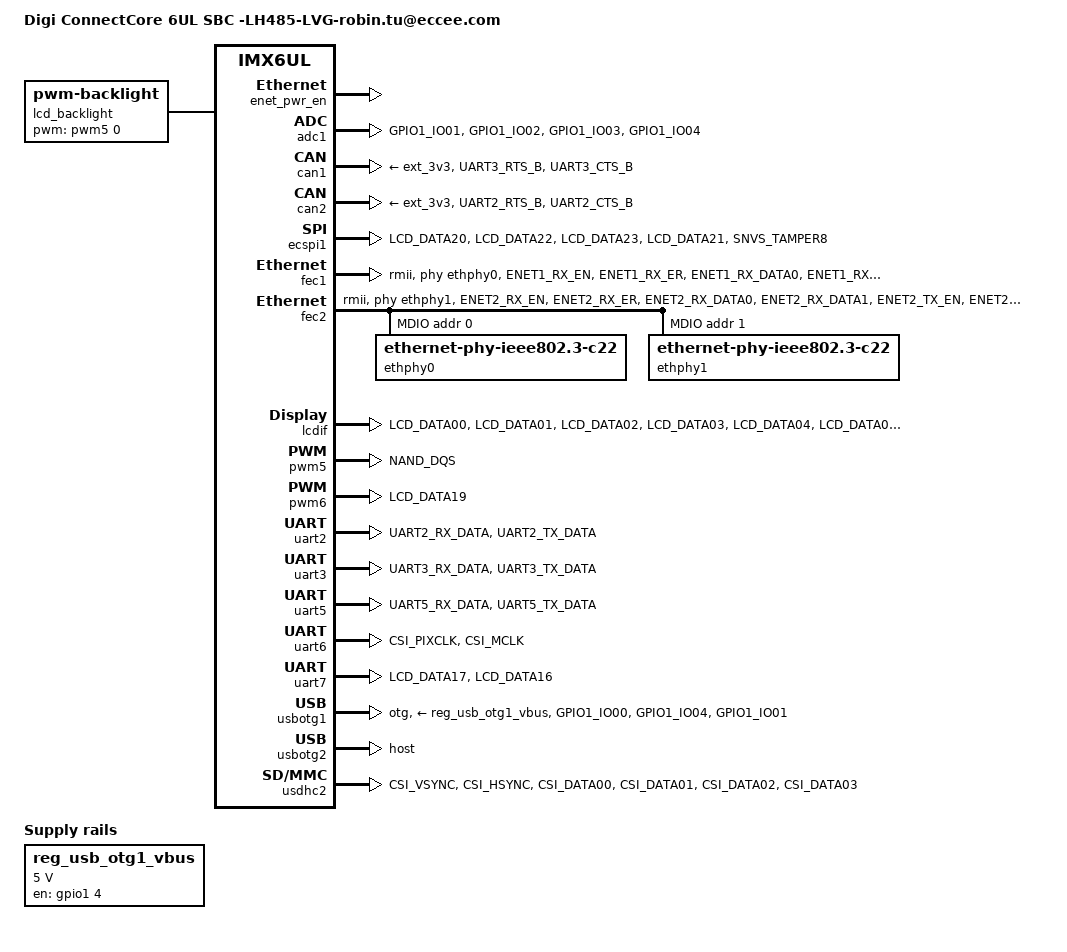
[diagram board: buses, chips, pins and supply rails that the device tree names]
/*
 * Device tree generated automatically by Digi ConnectCore Smart IOmux.
 *
 * This file is provided "AS IS" without any warranties and support, it is
 * just a guideline that requires additional customization.
 *
 * Please verify the calculated pin assignments with the hardware reference
 * manual for your platform, review the commented lines, and add the
 * specific values for your hardware.
 */

/dts-v1/;

#include <dt-bindings/input/input.h>
#include <dt-bindings/interrupt-controller/irq.h>
/* i.MX6 UltraLite CPU */
#include "imx6ul.dtsi"
/* ConnectCore 6UL (wireless/bluetooth variant) */
#include "imx6ul-ccimx6ul-wb.dtsi"

/ {
	// Add here your platform model.
	model = "Digi ConnectCore 6UL SBC -LH485-LVG-robin.tu@eccee.com ";
	// Add here your compatible platform.
	compatible = "digi,ccimx6ulsbc", "digi,ccimx6ul", "fsl,imx6ul";


	pxp_v4l2: pxp-v4l2 {
		compatible = "fsl,imx6ul-pxp-v4l2", "fsl,imx6sx-pxp-v4l2", "fsl,imx6sl-pxp-v4l2";
		status = "okay";
	};

	reg_usb_otg1_vbus: reg_usb_otg1@0 {
		compatible = "regulator-fixed";
		regulator-name = "usb_otg1_vbus";
		regulator-min-microvolt = <5000000>;
		regulator-max-microvolt = <5000000>;
		gpio = <&gpio1 4 GPIO_ACTIVE_HIGH>;
		enable-active-high;
	};

	sound_max98089: sound-max98089 {
		compatible = "fsl,imx-audio-max98088";
		model = "imx-max98088";
		cpu-dai = <&sai2>;
		audio-codec = <&max98089>;
		asrc-controller = <&asrc>;
		gpr = <&gpr>;
		audio-routing =
			"Headphone Jack", "HPL",
			"Headphone Jack", "HPR",
			"Ext Spk", "SPKL",
			"Ext Spk", "SPKR",
			"LineOut", "RECL",
			"LineOut", "RECR",
			"Mic1", "MIC1",
			"Mic2", "MIC2",
			"LineInA", "INA1",
			"LineInA", "INA2",
			"LineInB", "INB1",
			"LineInB", "INB2";
		status = "disabled";
	};

	enet_pwr_en {
                          enet-pwren-gpios = <&gpio1 5 GPIO_ACTIVE_HIGH>;
                          status = "okay";
	};

	lcd_backlight: backlight {
		compatible = "pwm-backlight";
		pwms = <&pwm5 0 50000>;
		brightness-levels = <0 4 8 16 32 64 128 255>;
		default-brightness-level = <6>;
		status = "okay";
	};
};

//&csi {
//	status = "disabled";
//
//	port {
//		csi_ep0: endpoint@0 {
//			remote-endpoint = <&ov5640_ep>;
//		};
//
//	};
//};

&adc1 {
	pinctrl-names = "default";
	pinctrl-0 = <&pinctrl_adc1>;
	adc-ch-list = <1 2 3 4>;
	status = "okay";
};

&can1 {
	pinctrl-names = "default";
	pinctrl-0 = <&pinctrl_flexcan1>;

	/*
	 * Optional field.
	 *
	 * Set the proper voltage regulator to power the
	 * transceiver if needed.
	 */
	xceiver-supply = <&ext_3v3>;

	status = "okay";
};

&can2 {
	pinctrl-names = "default";
	pinctrl-0 = <&pinctrl_flexcan2>;

	/*
	 * Optional field.
	 *
	 * Set the proper voltage regulator to power the
	 * transceiver if needed.
	 */
	xceiver-supply = <&ext_3v3>;

	status = "okay";
};

&ecspi1 {
	num-cs = <1>;
	cs-gpios = <&gpio3 26 GPIO_ACTIVE_LOW>;
	pinctrl-names = "default";
	status = "okay";

	/*
	 * Configure the GPIO that you selected as 'slave select'.
	 */
	//cs-gpios = <&gpio3 26 GPIO_ACTIVE_LOW>;

	/*
	 * ECSPI1 (as master)
	 */
	//pinctrl-0 = <&pinctrl_ecspi1>;
	pinctrl-0 = <&pinctrl_ecspi1_master>;

	/*
	 * Reference block.
	 *
	 * Add your slave devices here. Next is an example of spidev.
	 * Expect a harmless kernel warning if you enable spidev as slave.
	 */
	//spidev@0 {
	//	reg = <0>;
	//	compatible = "spidev";
	//	spi-max-frequency = <1000000>;
	//};

};

&fec1 {
	pinctrl-names = "default";
	pinctrl-0 = <&pinctrl_enet1>, <&pinctrl_enet1_gpio>;
	phy-mode = "rmii";
	phy-handle = <&ethphy0>;
	phy-reset-gpios = <&mca_gpio 7 GPIO_ACTIVE_LOW>;
	phy-reset-duration = <26>;
	digi,phy-reset-in-suspend;
	status = "okay";
};

&fec2 {
	pinctrl-names = "default";
	pinctrl-0 = <&pinctrl_enet2>,
		    <&pinctrl_enet2_mdio>,
		    <&pinctrl_enet2_gpio>;
	phy-mode = "rmii";
	phy-handle = <&ethphy1>;
	phy-reset-gpios = <&gpio5 6 GPIO_ACTIVE_LOW>;
	phy-reset-duration = <26>;
	digi,phy-reset-in-suspend;
	status = "okay";

	/*
	 * The MDIO bus is shared between ENET1 and ENET2. If you only want
	 * to enable ENET1, this node must be moved to fec1 node, and the
	 * pinctrl-0 of fec1 must contain the IOMUX for the MDIO bus on ENET1
	 * (pintrl_enet1_mdio).
	 */
	mdio {
		#address-cells = <1>;
		#size-cells = <0>;

		ethphy0: ethernet-phy@0 {
			compatible = "ethernet-phy-ieee802.3-c22";
			smsc,disable-energy-detect;
			reg = <0>;
		};

		ethphy1: ethernet-phy@1 {
			compatible = "ethernet-phy-ieee802.3-c22";
			smsc,disable-energy-detect;
			reg = <1>;
		};
	};
};


&i2c1 {

	max98089: codec@10 {
		compatible = "maxim,max98089";
		reg = <0x10>;
		clocks = <&clks IMX6UL_CLK_SAI2>;
		clock-names = "mclk";
		interrupt-parent = <&gpio5>;
		interrupts = <7 IRQ_TYPE_EDGE_FALLING>;
		status = "disabled";
	};

//	ov5640: ov5640@3c {
//		compatible = "ov5640";
//		reg = <0x3c>;
//		pinctrl-names = "default";
//		pinctrl-0 = <&pinctrl_csi>;
//		clocks = <&clks IMX6UL_CLK_CSI>;
//		clock-names = "csi_mclk";
//		pwn-gpios = <&mca_ioexp_gpio 31 GPIO_ACTIVE_LOW>;
//		rst-gpios = <&mca_ioexp_gpio 22 GPIO_ACTIVE_HIGH>;
//		csi_id = <0>;
//		mclk = <24000000>;
//		mclk_source = <0>;
//		status = "disabled";
//		digi,defer-probe;
//		port {
//			ov5640_ep: endpoint {
//				remote-endpoint = <&csi_ep0>;
//			};
//		};
//	};
};

&lcdif {
	pinctrl-names = "default";
	pinctrl-0 = <&pinctrl_lcdif>;
	/* Select one of the defined displays */
	display = <&hw480272>;
	status = "okay";

	/*
	 * Reference block.
	 *
	 * Define your display.
	 */
	hw480272: display@2 {
		bits-per-pixel = <16>;
		bus-width = <16>;

		display-timings {
			native-mode = <&timing3>;
			timing3: timing3 {
				clock-frequency = <9000000>;
				hactive = <480>;
				vactive = <272>;
				hfront-porch = <8>;
				hback-porch = <43>;
				hsync-len = <4>;
				vback-porch = <8>;
				vfront-porch = <8>;
				vsync-len = <6>;
				hsync-active = <0>;
				vsync-active = <0>;
				de-active = <1>;
				pixelclk-active = <0>;
			};
		};
	};
};

/* LCD backlight */
&pwm5 {
	pinctrl-names = "default";
	pinctrl-0 = <&pinctrl_pwm5>;
	status = "okay";
};

&pwm6 {
	pinctrl-names = "default";
	pinctrl-0 = <&pinctrl_pwm6>;
	status = "okay";
};

/* SAI2 */
&sai2 {
	pinctrl-names = "default", "sleep";
	pinctrl-0 = <&pinctrl_sai2>;
	pinctrl-1 = <&pinctrl_sai2_sleep>;
	assigned-clocks = <&clks IMX6UL_CLK_SAI2_SEL>,
			  <&clks IMX6UL_CLK_PLL4_AUDIO_DIV>,
			  <&clks IMX6UL_CLK_SAI2>;
	assigned-clock-rates = <0>, <786432000>, <12288000>;
	assigned-clock-parents = <&clks IMX6UL_CLK_PLL4_AUDIO_DIV>;
	status = "disabled";
};

&uart2 {
	pinctrl-names = "default";
	pinctrl-0 = <&pinctrl_uart2>;

	status = "okay";
};

&uart3 {
	pinctrl-names = "default";
	pinctrl-0 = <&pinctrl_uart3>;

	status = "okay";
};

&uart5 {
	pinctrl-names = "default";
	pinctrl-0 = <&pinctrl_console>;
	status = "okay";
};

&uart6 {
	pinctrl-names = "default";
	pinctrl-0 = <&pinctrl_uart6>;

	status = "okay";
};

&uart7 {
	pinctrl-names = "default";
	pinctrl-0 = <&pinctrl_uart7>;

	status = "okay";
};

&usbotg1 {
	dr_mode = "otg";

	/* Set the proper voltage regulator. */
	vbus-supply = <&reg_usb_otg1_vbus>;

	/*
	 * Configure the power line if needed.
	 */
	digi,power-line-active-high;

	/*
	 * Configure the overcurrent line if needed.
	 */
	//disable-over-current;

	pinctrl-0 = <&pinctrl_usbotg1>;

	status = "okay";
};

&usbotg2 {
	dr_mode = "host";

	/* Set the proper voltage regulator. */
	//vbus-supply = <&reg_usb_otg1_vbus>;

	/*
	 * Configure the power line if needed.
	 */
	digi,power-line-active-high;

	/*
	 * Configure the overcurrent line if needed.
	 */
	disable-over-current;

	status = "okay";
};

&usdhc2 {
	pinctrl-names = "default";
	pinctrl-0 = <&pinctrl_usdhc2>;
	//pinctrl-assert-gpios = <&gpio5 1 GPIO_ACTIVE_LOW>;
	broken-cd;      /* no carrier detect line (use polling) */
	no-1-8-v;
	status = "okay";
};

&iomuxc {
	pinctrl-names = "default";
	pinctrl-0 = <&pinctrl_hog>;

	imx6ul-ccimx6ul {
		pinctrl_adc1: adc1grp {
			fsl,pins = <
				MX6UL_PAD_GPIO1_IO01__GPIO1_IO01		0xb0
				MX6UL_PAD_GPIO1_IO02__GPIO1_IO02		0xb0
				MX6UL_PAD_GPIO1_IO03__GPIO1_IO03		0xb0
				MX6UL_PAD_GPIO1_IO04__GPIO1_IO04		0xb0
			>;
		};

		pinctrl_console: uart5grp {
			fsl,pins = <
				MX6UL_PAD_UART5_RX_DATA__UART5_DCE_RX		0x1b0b1
				MX6UL_PAD_UART5_TX_DATA__UART5_DCE_TX		0x1b0b1
			>;
		};

		pinctrl_ecspi1_master: ecspi1grp1 {
			fsl,pins = <
				MX6UL_PAD_LCD_DATA20__ECSPI1_SCLK	0x10b0
				MX6UL_PAD_LCD_DATA22__ECSPI1_MOSI	0x10b0
				MX6UL_PAD_LCD_DATA23__ECSPI1_MISO	0x10b0
				MX6UL_PAD_LCD_DATA21__GPIO3_IO26	0x10b0 /* Chip Select */
				/* SPI1_IRQ_N */
				MX6UL_PAD_SNVS_TAMPER8__GPIO5_IO08	0x1b0b0
			>;
		};
		
		pinctrl_ecspi1_slave: ecspi1grp2 {
			fsl,pins = <
				MX6UL_PAD_LCD_DATA20__ECSPI1_SCLK	0x10b0
				MX6UL_PAD_LCD_DATA22__ECSPI1_MOSI	0x10b0
				MX6UL_PAD_LCD_DATA23__ECSPI1_MISO	0x10b0
				MX6UL_PAD_LCD_DATA21__ECSPI1_SS0	0x10b0 /* Chip Select */
				/* SPI1_IRQ_N */
				MX6UL_PAD_SNVS_TAMPER8__GPIO5_IO08	0x1b0b0
			>;
		};

		pinctrl_enet1: enet1grp {
			fsl,pins = <
				MX6UL_PAD_ENET1_RX_EN__ENET1_RX_EN	0x1b0b0
				MX6UL_PAD_ENET1_RX_ER__ENET1_RX_ER	0x1b0b0
				MX6UL_PAD_ENET1_RX_DATA0__ENET1_RDATA00	0x1b0b0
				MX6UL_PAD_ENET1_RX_DATA1__ENET1_RDATA01	0x1b0b0
				MX6UL_PAD_ENET1_TX_EN__ENET1_TX_EN	0x1b0b0
				MX6UL_PAD_ENET1_TX_DATA0__ENET1_TDATA00	0x1b0b0
				MX6UL_PAD_ENET1_TX_DATA1__ENET1_TDATA01	0x1b0b0
				MX6UL_PAD_ENET1_TX_CLK__ENET1_REF_CLK1	0x4001b031
			>;
		};

		pinctrl_enet2: enet2grp {
			fsl,pins = <
				MX6UL_PAD_ENET2_RX_EN__ENET2_RX_EN	0x1b0b0
				MX6UL_PAD_ENET2_RX_ER__ENET2_RX_ER	0x1b0b0
				MX6UL_PAD_ENET2_RX_DATA0__ENET2_RDATA00	0x1b0b0
				MX6UL_PAD_ENET2_RX_DATA1__ENET2_RDATA01	0x1b0b0
				MX6UL_PAD_ENET2_TX_EN__ENET2_TX_EN	0x1b0b0
				MX6UL_PAD_ENET2_TX_DATA0__ENET2_TDATA00	0x1b0b0
				MX6UL_PAD_ENET2_TX_DATA1__ENET2_TDATA01	0x1b0b0
				MX6UL_PAD_ENET2_TX_CLK__ENET2_REF_CLK2	0x4001b031
			>;
		};

		pinctrl_enet1_mdio: mdioenet1grp {
			fsl,pins = <
				MX6UL_PAD_GPIO1_IO07__ENET1_MDC		0x1b0b0
				MX6UL_PAD_GPIO1_IO06__ENET1_MDIO	0x1b0b0
			>;
		};

		pinctrl_enet2_mdio: mdioenet2grp {
			fsl,pins = <
				MX6UL_PAD_GPIO1_IO07__ENET2_MDC		0x1b0b0
				MX6UL_PAD_GPIO1_IO06__ENET2_MDIO	0x1b0b0
			>;
		};

		pinctrl_enet1_gpio: enet1gpiogrp {
			fsl,pins = <
				/* ENET1_INT */
				MX6UL_PAD_GPIO1_IO08__GPIO1_IO08	0x1b0b0
			>;
		};

		pinctrl_enet2_gpio: enet2gpiogrp {
			fsl,pins = <
				/* PHY reset */
				MX6UL_PAD_SNVS_TAMPER6__GPIO5_IO06	0x0b0b0
				/* ENET2_INT */
				MX6UL_PAD_GPIO1_IO09__GPIO1_IO09	0x1b0b0
			>;
		};

		pinctrl_flexcan1: flexcan1grp {
			fsl,pins = <
				MX6UL_PAD_UART3_RTS_B__FLEXCAN1_RX		0x1b020
				MX6UL_PAD_UART3_CTS_B__FLEXCAN1_TX		0x1b020
			>;
		};

		pinctrl_flexcan2: flexcan2grp {
			fsl,pins = <
				MX6UL_PAD_UART2_RTS_B__FLEXCAN2_RX		0x1b020
				MX6UL_PAD_UART2_CTS_B__FLEXCAN2_TX		0x1b020
			>;
		};

        pinctrl_hog: hoggrp {
            fsl,pins = <
		/* GPIO1_IO05[ENET_PWR_EN] */
                MX6UL_PAD_GPIO1_IO05__GPIO1_IO05                0x1b0b0
                /* GPIO5_IO05[EXP_I2C_IRQ_N] */
                MX6UL_PAD_SNVS_TAMPER5__GPIO5_IO05              0x1b0b0
            >;
                };


		pinctrl_lcdif: lcdifgrp {
			fsl,pins = <
				MX6UL_PAD_LCD_DATA00__LCDIF_DATA00		0x79
				MX6UL_PAD_LCD_DATA01__LCDIF_DATA01		0x79
				MX6UL_PAD_LCD_DATA02__LCDIF_DATA02		0x79
				MX6UL_PAD_LCD_DATA03__LCDIF_DATA03		0x79
				MX6UL_PAD_LCD_DATA04__LCDIF_DATA04		0x79
				MX6UL_PAD_LCD_DATA05__LCDIF_DATA05		0x79
				MX6UL_PAD_LCD_DATA06__LCDIF_DATA06		0x79
				MX6UL_PAD_LCD_DATA07__LCDIF_DATA07		0x79
				MX6UL_PAD_LCD_DATA08__LCDIF_DATA08		0x79
				MX6UL_PAD_LCD_DATA09__LCDIF_DATA09		0x79
				MX6UL_PAD_LCD_DATA10__LCDIF_DATA10		0x79
				MX6UL_PAD_LCD_DATA11__LCDIF_DATA11		0x79
				MX6UL_PAD_LCD_DATA12__LCDIF_DATA12		0x79
				MX6UL_PAD_LCD_DATA13__LCDIF_DATA13		0x79
				MX6UL_PAD_LCD_DATA14__LCDIF_DATA14		0x79
				MX6UL_PAD_LCD_DATA15__LCDIF_DATA15		0x79
				MX6UL_PAD_LCD_ENABLE__LCDIF_ENABLE		0x79
				MX6UL_PAD_LCD_CLK__LCDIF_CLK		0x17050
				MX6UL_PAD_LCD_HSYNC__LCDIF_HSYNC		0x79
				MX6UL_PAD_LCD_VSYNC__LCDIF_VSYNC		0x79
				MX6UL_PAD_LCD_RESET__LCDIF_RESET		0x79
			>;
		};

		pinctrl_pwm5: pwm5grp {
			fsl,pins = <
				MX6UL_PAD_NAND_DQS__PWM5_OUT		0x110b0
			>;
		};

		pinctrl_pwm6: pwm6grp {
			fsl,pins = <
				MX6UL_PAD_LCD_DATA19__PWM6_OUT		0x110b0
			>;
		};

		pinctrl_sai2: sai2grp {
			fsl,pins = <
				MX6UL_PAD_JTAG_TRST_B__SAI2_TX_DATA	0x11088
				MX6UL_PAD_JTAG_TCK__SAI2_RX_DATA	0x11088
				MX6UL_PAD_JTAG_TMS__SAI2_MCLK		0x17088
				MX6UL_PAD_JTAG_TDI__SAI2_TX_BCLK	0x17088
				MX6UL_PAD_JTAG_TDO__SAI2_TX_SYNC	0x17088
				/* Interrupt */
				MX6UL_PAD_SNVS_TAMPER7__GPIO5_IO07	0x80000000
			>;
		};

		pinctrl_sai2_sleep: sai2grp_sleep {
			fsl,pins = <
				MX6UL_PAD_JTAG_TRST_B__GPIO1_IO15	0x3000
				MX6UL_PAD_JTAG_TCK__GPIO1_IO14		0x3000
				MX6UL_PAD_JTAG_TMS__GPIO1_IO11		0x3000
				MX6UL_PAD_JTAG_TDO__GPIO1_IO12		0x3000
				/* Interrupt */
				MX6UL_PAD_SNVS_TAMPER7__GPIO5_IO07	0x3000
			>;
		};

		pinctrl_uart2: uart2grp {
			fsl,pins = <
				MX6UL_PAD_UART2_RX_DATA__UART2_DCE_RX		0x1b0b1
				MX6UL_PAD_UART2_TX_DATA__UART2_DCE_TX		0x1b0b1
			>;
		};

		pinctrl_uart3: uart3grp {
			fsl,pins = <
				MX6UL_PAD_UART3_RX_DATA__UART3_DCE_RX		0x1b0b1
				MX6UL_PAD_UART3_TX_DATA__UART3_DCE_TX		0x1b0b1
			>;
		};

		pinctrl_uart6: uart6grp {
			fsl,pins = <
				MX6UL_PAD_CSI_PIXCLK__UART6_DCE_RX		0x1b0b1
				MX6UL_PAD_CSI_MCLK__UART6_DCE_TX		0x1b0b1
			>;
		};

		pinctrl_uart7: uart7grp {
			fsl,pins = <
				MX6UL_PAD_LCD_DATA17__UART7_DCE_RX		0x1b0b1
				MX6UL_PAD_LCD_DATA16__UART7_DCE_TX		0x1b0b1
			>;
		};

		pinctrl_usbotg1: usbotg1grp {
			fsl,pins = <
				MX6UL_PAD_GPIO1_IO00__ANATOP_OTG1_ID	0x17059
				MX6UL_PAD_GPIO1_IO04__GPIO1_IO04	0x17059 /* USBOTG1 PWR */
				MX6UL_PAD_GPIO1_IO01__USB_OTG1_OC	0x17059
			>;
		};

		pinctrl_usdhc2: usdhc2grp {
			fsl,pins = <
				MX6UL_PAD_CSI_VSYNC__USDHC2_CLK		0x10039
				MX6UL_PAD_CSI_HSYNC__USDHC2_CMD		0x17059
				MX6UL_PAD_CSI_DATA00__USDHC2_DATA0		0x17059
				MX6UL_PAD_CSI_DATA01__USDHC2_DATA1		0x17059
				MX6UL_PAD_CSI_DATA02__USDHC2_DATA2		0x17059
				MX6UL_PAD_CSI_DATA03__USDHC2_DATA3		0x17059
			>;
		};
	};
};
